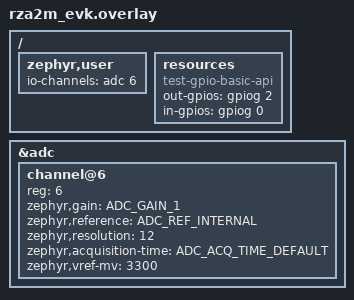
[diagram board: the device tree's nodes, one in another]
/*
 * Copyright (c) 2025 Renesas Electronics Corporation
 *
 * SPDX-License-Identifier: Apache-2.0
 */

/ {
	zephyr,user {
		io-channels = <&adc 6>;
	};
};

&adc {
	status = "okay";
	#address-cells = <1>;
	#size-cells = <0>;

	channel@6 {
		reg = <6>;
		zephyr,gain = "ADC_GAIN_1";
		zephyr,reference = "ADC_REF_INTERNAL";
		zephyr,resolution = <12>;
		zephyr,acquisition-time = <ADC_ACQ_TIME_DEFAULT>;
		zephyr,vref-mv = <3300>;
	};
};

#include <zephyr/dt-bindings/gpio/renesas-rza2m-gpio.h>

/ {
	resources {
		compatible = "test-gpio-basic-api";
		out-gpios = <&gpiog 2 0>;
		in-gpios = <&gpiog 0 0>;
		status = "okay";
	};
};
